VERSION ""

NS_ :

BS_:

BU_: DLG

BO_ 100 DD_TMP_102_Data: 8 Vector__XXX
 SG_ DD_TMP_102_temperature_raw : 0|16@1+ (1,-32768) [-32768|32767] "LSB" Vector__XXX
 SG_ DD_TMP_102_temperature_deg : 16|14@1+ (0.01,-81.92) [-81.92|81.91] "°C" Vector__XXX

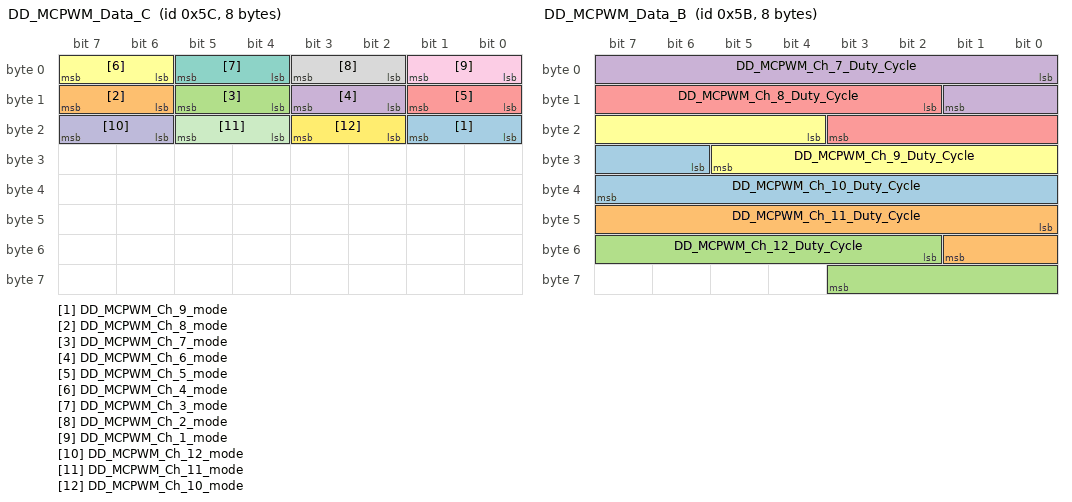
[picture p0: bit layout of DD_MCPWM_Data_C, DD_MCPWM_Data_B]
BO_ 92 DD_MCPWM_Data_C: 8 Vector__XXX
 SG_ DD_MCPWM_Ch_9_mode : 16|2@1+ (1,0) [0|3] "" Vector__XXX
 SG_ DD_MCPWM_Ch_8_mode : 14|2@1+ (1,0) [0|3] "" Vector__XXX
 SG_ DD_MCPWM_Ch_7_mode : 12|2@1+ (1,0) [0|3] "" Vector__XXX
 SG_ DD_MCPWM_Ch_6_mode : 10|2@1+ (1,0) [0|3] "" Vector__XXX
 SG_ DD_MCPWM_Ch_5_mode : 8|2@1+ (1,0) [0|3] "" Vector__XXX
 SG_ DD_MCPWM_Ch_4_mode : 6|2@1+ (1,0) [0|3] "" Vector__XXX
 SG_ DD_MCPWM_Ch_3_mode : 4|2@1+ (1,0) [0|3] "" Vector__XXX
 SG_ DD_MCPWM_Ch_2_mode : 2|2@1+ (1,0) [0|3] "" Vector__XXX
 SG_ DD_MCPWM_Ch_1_mode : 0|2@1+ (1,0) [0|3] "" Vector__XXX
 SG_ DD_MCPWM_Ch_12_mode : 22|2@1+ (1,0) [0|3] "" Vector__XXX
 SG_ DD_MCPWM_Ch_11_mode : 20|2@1+ (1,0) [0|3] "" Vector__XXX
 SG_ DD_MCPWM_Ch_10_mode : 18|2@1+ (1,0) [0|3] "" Vector__XXX

BO_ 91 DD_MCPWM_Data_B: 8 Vector__XXX
 SG_ DD_MCPWM_Ch_10_Duty_Cycle : 30|10@1+ (0.1,0) [0|102.3] "%" Vector__XXX
 SG_ DD_MCPWM_Ch_11_Duty_Cycle : 40|10@1+ (0.1,0) [0|102.3] "%" Vector__XXX
 SG_ DD_MCPWM_Ch_12_Duty_Cycle : 50|10@1+ (0.1,0) [0|102.3] "%" Vector__XXX
 SG_ DD_MCPWM_Ch_7_Duty_Cycle : 0|10@1+ (0.1,0) [0|102.3] "%" Vector__XXX
 SG_ DD_MCPWM_Ch_8_Duty_Cycle : 10|10@1+ (0.1,0) [0|102.3] "%" Vector__XXX
 SG_ DD_MCPWM_Ch_9_Duty_Cycle : 20|10@1+ (0.1,0) [0|102.3] "%" Vector__XXX

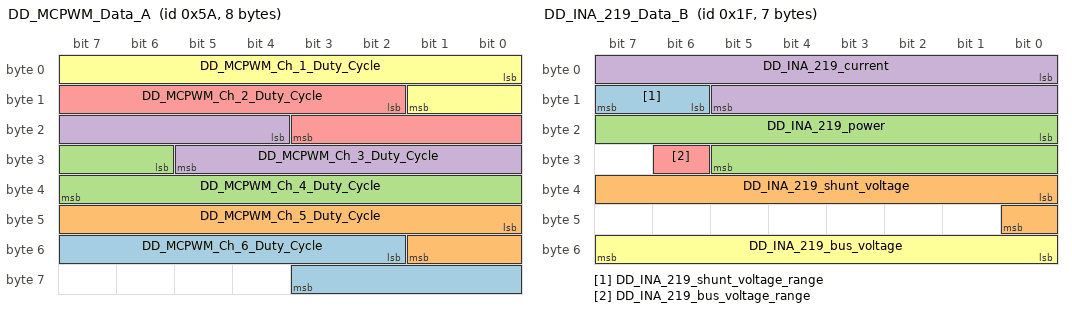
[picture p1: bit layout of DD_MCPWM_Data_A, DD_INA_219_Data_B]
BO_ 90 DD_MCPWM_Data_A: 8 DLG
 SG_ DD_MCPWM_Ch_6_Duty_Cycle : 50|10@1+ (0.1,0) [0|102.3] "%" Vector__XXX
 SG_ DD_MCPWM_Ch_5_Duty_Cycle : 40|10@1+ (0.1,0) [0|102.3] "%" Vector__XXX
 SG_ DD_MCPWM_Ch_4_Duty_Cycle : 30|10@1+ (0.1,0) [0|102.3] "%" Vector__XXX
 SG_ DD_MCPWM_Ch_3_Duty_Cycle : 20|10@1+ (0.1,0) [0|102.3] "%" Vector__XXX
 SG_ DD_MCPWM_Ch_2_Duty_Cycle : 10|10@1+ (0.1,0) [0|102.3] "%" Vector__XXX
 SG_ DD_MCPWM_Ch_1_Duty_Cycle : 0|10@1+ (0.1,0) [0|102.3] "%" Vector__XXX

BO_ 31 DD_INA_219_Data_B: 7 DLG
 SG_ DD_INA_219_shunt_voltage_range : 14|2@1+ (1,0) [0|3] "" Vector__XXX
 SG_ DD_INA_219_shunt_voltage : 32|9@1+ (0.1,0) [0|51.1] "mV" Vector__XXX
 SG_ DD_INA_219_power : 16|14@1+ (0.1,0) [0|1638.3] "mW" Vector__XXX
 SG_ DD_INA_219_current : 0|14@1+ (0.1,0) [0|1638.3] "mA" Vector__XXX
 SG_ DD_INA_219_bus_voltage_range : 30|1@1+ (1,0) [0|1] "" Vector__XXX
 SG_ DD_INA_219_bus_voltage : 48|8@1+ (0.1,0) [0|25.5] "V" Vector__XXX

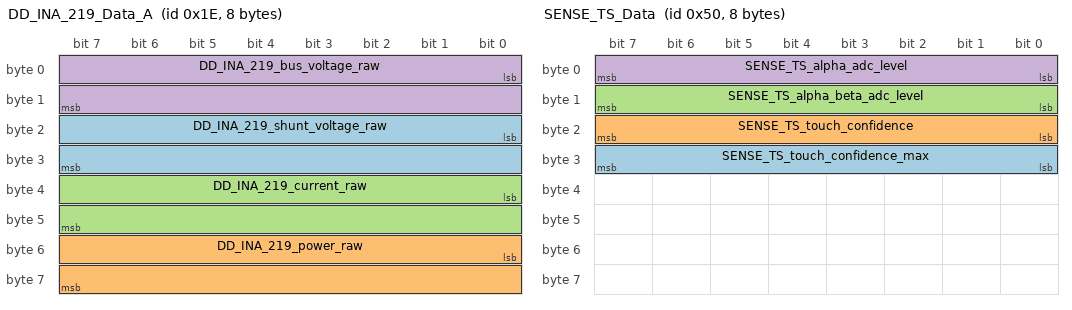
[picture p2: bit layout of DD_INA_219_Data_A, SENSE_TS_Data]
BO_ 30 DD_INA_219_Data_A: 8 DLG
 SG_ DD_INA_219_shunt_voltage_raw : 16|16@1+ (1,-32768) [-32768|32767] "LSB" Vector__XXX
 SG_ DD_INA_219_power_raw : 48|16@1+ (1,0) [0|65535] "LSB" Vector__XXX
 SG_ DD_INA_219_current_raw : 32|16@1+ (1,-32768) [-32768|32767] "LSB" Vector__XXX
 SG_ DD_INA_219_bus_voltage_raw : 0|16@1+ (1,0) [0|65535] "LSB" Vector__XXX

BO_ 80 SENSE_TS_Data: 8 DLG
 SG_ SENSE_TS_touch_confidence_max : 24|8@1+ (0.01,0) [0|2.55] "" Vector__XXX
 SG_ SENSE_TS_touch_confidence : 16|8@1+ (0.01,0) [0|2.55] "" Vector__XXX
 SG_ SENSE_TS_alpha_beta_adc_level : 8|8@1+ (0.01,0) [0|2.55] "" Vector__XXX
 SG_ SENSE_TS_alpha_adc_level : 0|8@1+ (0.01,0) [0|2.55] "" Vector__XXX

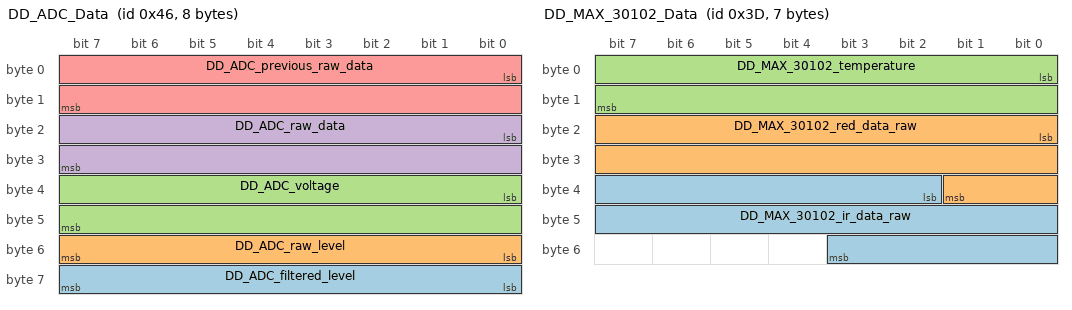
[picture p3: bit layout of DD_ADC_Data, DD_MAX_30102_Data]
BO_ 70 DD_ADC_Data: 8 DLG
 SG_ DD_ADC_filtered_level : 56|8@1+ (0.01,0) [0|2.55] "" Vector__XXX
 SG_ DD_ADC_raw_level : 48|8@1+ (0.01,0) [0|2.55] "" Vector__XXX
 SG_ DD_ADC_voltage : 32|16@1+ (1,0) [0|65535] "mV" Vector__XXX
 SG_ DD_ADC_raw_data : 16|16@1+ (1,0) [0|65535] "" Vector__XXX
 SG_ DD_ADC_previous_raw_data : 0|16@1+ (1,0) [0|65535] "" Vector__XXX

BO_ 61 DD_MAX_30102_Data: 7 DLG
 SG_ DD_MAX_30102_ir_data_raw : 34|18@1+ (1,0) [0|262143] "" Vector__XXX
 SG_ DD_MAX_30102_red_data_raw : 16|18@1+ (1,0) [0|262143] "" Vector__XXX
 SG_ DD_MAX_30102_temperature : 0|16@1+ (0.01,-327.68) [-327.68|327.67] "deg" Vector__XXX

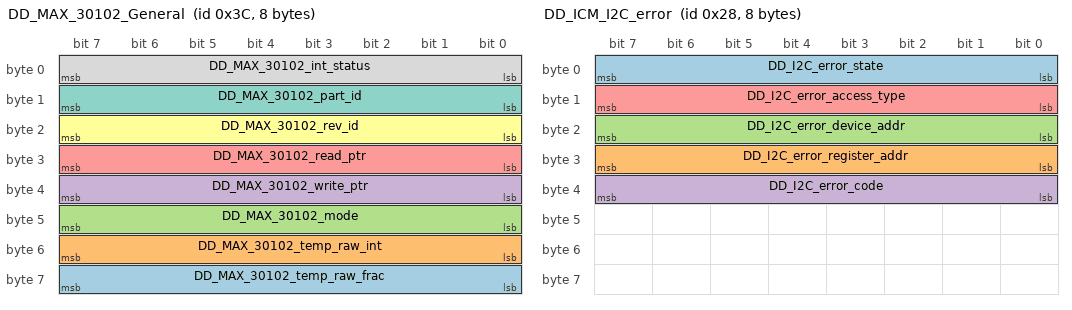
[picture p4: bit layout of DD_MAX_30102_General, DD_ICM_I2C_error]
BO_ 60 DD_MAX_30102_General: 8 DLG
 SG_ DD_MAX_30102_temp_raw_frac : 56|8@1+ (1,0) [0|255] "" Vector__XXX
 SG_ DD_MAX_30102_temp_raw_int : 48|8@1+ (1,0) [0|255] "" Vector__XXX
 SG_ DD_MAX_30102_mode : 40|8@1+ (1,0) [0|255] "" Vector__XXX
 SG_ DD_MAX_30102_write_ptr : 32|8@1+ (1,0) [0|255] "" Vector__XXX
 SG_ DD_MAX_30102_read_ptr : 24|8@1+ (1,0) [0|255] "" Vector__XXX
 SG_ DD_MAX_30102_rev_id : 16|8@1+ (1,0) [0|255] "" Vector__XXX
 SG_ DD_MAX_30102_part_id : 8|8@1+ (1,0) [0|255] "" Vector__XXX
 SG_ DD_MAX_30102_int_status : 0|8@1+ (1,0) [0|255] "" Vector__XXX

BO_ 50 DLG_LOG_General: 1 DLG
 SG_ DLG_LOG_global_msg_counter : 0|8@1+ (1,0) [0|255] "" Vector__XXX

BO_ 40 DD_ICM_I2C_error: 8 DLG
 SG_ DD_I2C_error_state : 0|8@1+ (1,0) [0|255] "" Vector__XXX
 SG_ DD_I2C_error_register_addr : 24|8@1+ (1,0) [0|255] "" Vector__XXX
 SG_ DD_I2C_error_device_addr : 16|8@1+ (1,0) [0|255] "" Vector__XXX
 SG_ DD_I2C_error_code : 32|8@1+ (1,-128) [-128|127] "" Vector__XXX
 SG_ DD_I2C_error_access_type : 8|8@1+ (1,0) [0|255] "" Vector__XXX

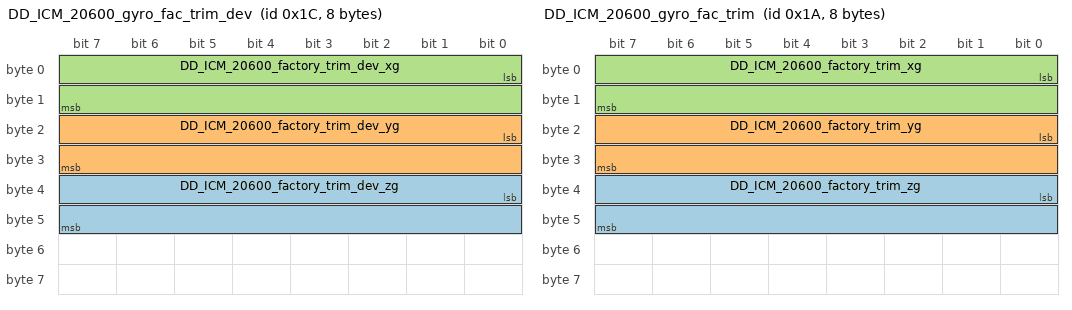
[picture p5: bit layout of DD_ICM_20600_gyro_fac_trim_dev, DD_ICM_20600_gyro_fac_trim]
BO_ 28 DD_ICM_20600_gyro_fac_trim_dev: 8 DLG
 SG_ DD_ICM_20600_factory_trim_dev_zg : 32|16@1+ (0.001,-32.768) [-32.768|32.767] "" Vector__XXX
 SG_ DD_ICM_20600_factory_trim_dev_yg : 16|16@1+ (0.001,-32.768) [-32.768|32.767] "" Vector__XXX
 SG_ DD_ICM_20600_factory_trim_dev_xg : 0|16@1+ (0.001,-32.768) [-32.768|32.767] "" Vector__XXX

BO_ 26 DD_ICM_20600_gyro_fac_trim: 8 DLG
 SG_ DD_ICM_20600_factory_trim_zg : 32|16@1+ (1,-32768) [-32768|32767] "" Vector__XXX
 SG_ DD_ICM_20600_factory_trim_yg : 16|16@1+ (1,-32768) [-32768|32767] "" Vector__XXX
 SG_ DD_ICM_20600_factory_trim_xg : 0|16@1+ (1,-32768) [-32768|32767] "" Vector__XXX

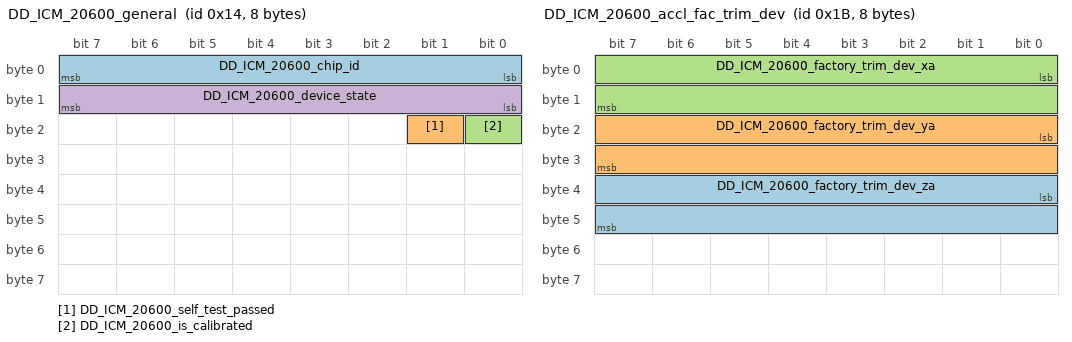
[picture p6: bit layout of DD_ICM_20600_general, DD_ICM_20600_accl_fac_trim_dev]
BO_ 20 DD_ICM_20600_general: 8 DLG
 SG_ DD_ICM_20600_chip_id : 0|8@1+ (1,0) [0|255] "" Vector__XXX
 SG_ DD_ICM_20600_self_test_passed : 17|1@1+ (1,0) [0|1] "" Vector__XXX
 SG_ DD_ICM_20600_is_calibrated : 16|1@1+ (1,0) [0|1] "" Vector__XXX
 SG_ DD_ICM_20600_device_state : 8|8@1+ (1,0) [0|255] "" Vector__XXX

BO_ 27 DD_ICM_20600_accl_fac_trim_dev: 8 DLG
 SG_ DD_ICM_20600_factory_trim_dev_za : 32|16@1+ (0.001,-32.768) [-32.768|32.767] "" Vector__XXX
 SG_ DD_ICM_20600_factory_trim_dev_ya : 16|16@1+ (0.001,-32.768) [-32.768|32.767] "" Vector__XXX
 SG_ DD_ICM_20600_factory_trim_dev_xa : 0|16@1+ (0.001,-32.768) [-32.768|32.767] "" Vector__XXX

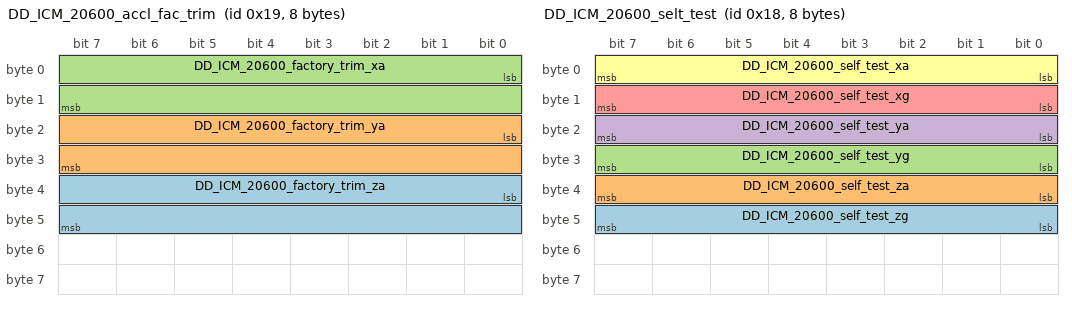
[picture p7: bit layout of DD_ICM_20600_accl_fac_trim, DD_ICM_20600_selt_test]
BO_ 25 DD_ICM_20600_accl_fac_trim: 8 DLG
 SG_ DD_ICM_20600_factory_trim_za : 32|16@1+ (1,-32768) [-32768|32767] "" Vector__XXX
 SG_ DD_ICM_20600_factory_trim_ya : 16|16@1+ (1,-32768) [-32768|32767] "" Vector__XXX
 SG_ DD_ICM_20600_factory_trim_xa : 0|16@1+ (1,-32768) [-32768|32767] "" Vector__XXX

BO_ 24 DD_ICM_20600_selt_test: 8 DLG
 SG_ DD_ICM_20600_self_test_zg : 40|8@1+ (1,0) [0|255] "" Vector__XXX
 SG_ DD_ICM_20600_self_test_za : 32|8@1+ (1,0) [0|255] "" Vector__XXX
 SG_ DD_ICM_20600_self_test_yg : 24|8@1+ (1,0) [0|255] "" Vector__XXX
 SG_ DD_ICM_20600_self_test_ya : 16|8@1+ (1,0) [0|255] "" Vector__XXX
 SG_ DD_ICM_20600_self_test_xg : 8|8@1+ (1,0) [0|255] "" Vector__XXX
 SG_ DD_ICM_20600_self_test_xa : 0|8@1+ (1,0) [0|255] "" Vector__XXX

BO_ 23 DD_ICM_20600_temperature: 8 DLG
 SG_ DD_ICM_20600_temperature_deg : 16|16@1+ (0.01,-327.68) [-327.68|327.67] "deg" Vector__XXX
 SG_ DD_ICM_20600_temperature_raw : 0|16@1+ (1,0) [0|65535] "" Vector__XXX

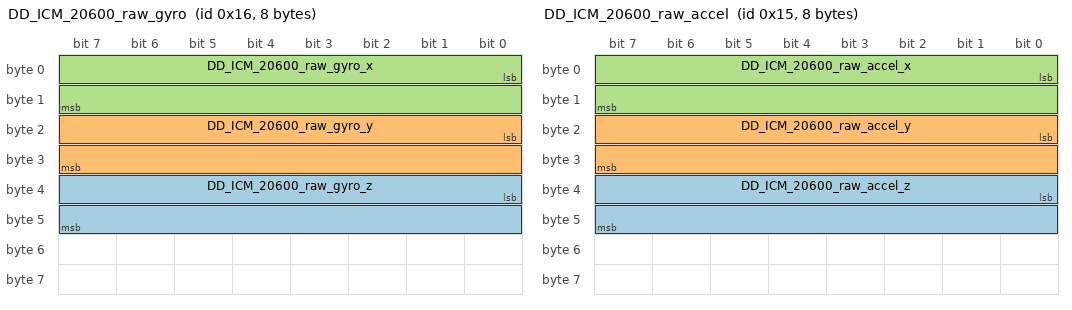
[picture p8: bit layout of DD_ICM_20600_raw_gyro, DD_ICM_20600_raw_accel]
BO_ 22 DD_ICM_20600_raw_gyro: 8 DLG
 SG_ DD_ICM_20600_raw_gyro_z : 32|16@1+ (1,-32768) [-32768|32767] "" Vector__XXX
 SG_ DD_ICM_20600_raw_gyro_y : 16|16@1+ (1,-32768) [-32768|32767] "" Vector__XXX
 SG_ DD_ICM_20600_raw_gyro_x : 0|16@1+ (1,-32768) [-32768|32767] "" Vector__XXX

BO_ 21 DD_ICM_20600_raw_accel: 8 DLG
 SG_ DD_ICM_20600_raw_accel_z : 32|16@1+ (1,-32768) [-32768|32767] "" Vector__XXX
 SG_ DD_ICM_20600_raw_accel_y : 16|16@1+ (1,-32768) [-32768|32767] "" Vector__XXX
 SG_ DD_ICM_20600_raw_accel_x : 0|16@1+ (1,-32768) [-32768|32767] "" Vector__XXX

CM_ SG_ 100 DD_TMP_102_temperature_raw "Current temperature reading in LSB (0.0625°C / LSB)";
CM_ SG_ 100 DD_TMP_102_temperature_deg "Current temperature reading in °C";
CM_ SG_ 92 DD_MCPWM_Ch_9_mode "Current alpha filtered ADC value";
CM_ SG_ 92 DD_MCPWM_Ch_8_mode "Current alpha filtered ADC value";
CM_ SG_ 92 DD_MCPWM_Ch_7_mode "Current alpha filtered ADC value";
CM_ SG_ 92 DD_MCPWM_Ch_6_mode "Current alpha filtered ADC value";
CM_ SG_ 92 DD_MCPWM_Ch_5_mode "Current alpha filtered ADC value";
CM_ SG_ 92 DD_MCPWM_Ch_4_mode "Current alpha filtered ADC value";
CM_ SG_ 92 DD_MCPWM_Ch_3_mode "Current alpha filtered ADC value";
CM_ SG_ 92 DD_MCPWM_Ch_2_mode "Current alpha filtered ADC value";
CM_ SG_ 92 DD_MCPWM_Ch_1_mode "Current alpha filtered ADC value";
CM_ SG_ 92 DD_MCPWM_Ch_12_mode "Current alpha filtered ADC value";
CM_ SG_ 92 DD_MCPWM_Ch_11_mode "Current alpha filtered ADC value";
CM_ SG_ 92 DD_MCPWM_Ch_10_mode "Current alpha filtered ADC value";
CM_ SG_ 91 DD_MCPWM_Ch_10_Duty_Cycle "Current alpha filtered ADC value";
CM_ SG_ 91 DD_MCPWM_Ch_11_Duty_Cycle "Current alpha filtered ADC value";
CM_ SG_ 91 DD_MCPWM_Ch_12_Duty_Cycle "Current alpha filtered ADC value";
CM_ SG_ 91 DD_MCPWM_Ch_7_Duty_Cycle "Current alpha filtered ADC value";
CM_ SG_ 91 DD_MCPWM_Ch_8_Duty_Cycle "Current alpha filtered ADC value";
CM_ SG_ 91 DD_MCPWM_Ch_9_Duty_Cycle "Current alpha filtered ADC value";
CM_ SG_ 90 DD_MCPWM_Ch_6_Duty_Cycle "Current alpha filtered ADC value";
CM_ SG_ 90 DD_MCPWM_Ch_5_Duty_Cycle "Current alpha filtered ADC value";
CM_ SG_ 90 DD_MCPWM_Ch_4_Duty_Cycle "Current alpha filtered ADC value";
CM_ SG_ 90 DD_MCPWM_Ch_3_Duty_Cycle "Current alpha filtered ADC value";
CM_ SG_ 90 DD_MCPWM_Ch_2_Duty_Cycle "Current alpha filtered ADC value";
CM_ SG_ 90 DD_MCPWM_Ch_1_Duty_Cycle "Current alpha filtered ADC value";
CM_ SG_ 31 DD_INA_219_shunt_voltage_range "Current alpha filtered ADC value";
CM_ SG_ 31 DD_INA_219_shunt_voltage "Current alpha filtered ADC value";
CM_ SG_ 31 DD_INA_219_power "Current alpha filtered ADC value";
CM_ SG_ 31 DD_INA_219_current "Current alpha filtered ADC value";
CM_ SG_ 31 DD_INA_219_bus_voltage_range "Current alpha filtered ADC value";
CM_ SG_ 31 DD_INA_219_bus_voltage "Current alpha filtered ADC value";
CM_ SG_ 30 DD_INA_219_shunt_voltage_raw "Current alpha filtered ADC value";
CM_ SG_ 30 DD_INA_219_power_raw "Current alpha filtered ADC value";
CM_ SG_ 30 DD_INA_219_current_raw "Current alpha filtered ADC value";
CM_ SG_ 30 DD_INA_219_bus_voltage_raw "Current alpha filtered ADC value";
CM_ SG_ 80 SENSE_TS_touch_confidence_max "Maximum touch confidence with a range of 0.0 to 1.0";
CM_ SG_ 80 SENSE_TS_touch_confidence "Touch confidence with a range of 0.0 to 1.0";
CM_ SG_ 80 SENSE_TS_alpha_beta_adc_level "Current alpha/beta  filtered ADC value";
CM_ SG_ 80 SENSE_TS_alpha_adc_level "Current alpha filtered ADC value";
BA_DEF_ SG_  "GenSigSendType" ENUM  "Cyclic","OnWrite","OnWriteWithRepetition","OnChange","OnChangeWithRepetition","IfActive","IfActiveWithRepetition","NoSigSendType";
BA_DEF_  "DBName" STRING ;
BA_DEF_ BO_  "GenMsgSendType" ENUM  "Cyclic","not_used","not_used","not_used","not_used","Cyclic","not_used","IfActive","NoMsgSendType";
BA_DEF_  "BusType" STRING ;
BA_DEF_DEF_  "GenSigSendType" "Cyclic";
BA_DEF_DEF_  "DBName" "";
BA_DEF_DEF_  "GenMsgSendType" "NoMsgSendType";
BA_DEF_DEF_  "BusType" "";
BA_ "BusType" "CAN";
BA_ "DBName" "DLG";
VAL_ 92 DD_MCPWM_Ch_9_mode 2 "DD_MCPWM_MODE_PWM" 1 "DD_MCPWM_MODE_ON" 0 "DD_MCPWM_MODE_OFF" ;
VAL_ 92 DD_MCPWM_Ch_8_mode 2 "DD_MCPWM_MODE_PWM" 1 "DD_MCPWM_MODE_ON" 0 "DD_MCPWM_MODE_OFF" ;
VAL_ 92 DD_MCPWM_Ch_7_mode 2 "DD_MCPWM_MODE_PWM" 1 "DD_MCPWM_MODE_ON" 0 "DD_MCPWM_MODE_OFF" ;
VAL_ 92 DD_MCPWM_Ch_6_mode 2 "DD_MCPWM_MODE_PWM" 1 "DD_MCPWM_MODE_ON" 0 "DD_MCPWM_MODE_OFF" ;
VAL_ 92 DD_MCPWM_Ch_5_mode 2 "DD_MCPWM_MODE_PWM" 1 "DD_MCPWM_MODE_ON" 0 "DD_MCPWM_MODE_OFF" ;
VAL_ 92 DD_MCPWM_Ch_4_mode 2 "DD_MCPWM_MODE_PWM" 1 "DD_MCPWM_MODE_ON" 0 "DD_MCPWM_MODE_OFF" ;
VAL_ 92 DD_MCPWM_Ch_3_mode 2 "DD_MCPWM_MODE_PWM" 1 "DD_MCPWM_MODE_ON" 0 "DD_MCPWM_MODE_OFF" ;
VAL_ 92 DD_MCPWM_Ch_2_mode 2 "DD_MCPWM_MODE_PWM" 1 "DD_MCPWM_MODE_ON" 0 "DD_MCPWM_MODE_OFF" ;
VAL_ 92 DD_MCPWM_Ch_1_mode 2 "DD_MCPWM_MODE_PWM" 1 "DD_MCPWM_MODE_ON" 0 "DD_MCPWM_MODE_OFF" ;
VAL_ 92 DD_MCPWM_Ch_12_mode 2 "DD_MCPWM_MODE_PWM" 1 "DD_MCPWM_MODE_ON" 0 "DD_MCPWM_MODE_OFF" ;
VAL_ 92 DD_MCPWM_Ch_11_mode 2 "DD_MCPWM_MODE_PWM" 1 "DD_MCPWM_MODE_ON" 0 "DD_MCPWM_MODE_OFF" ;
VAL_ 92 DD_MCPWM_Ch_10_mode 2 "DD_MCPWM_MODE_PWM" 1 "DD_MCPWM_MODE_ON" 0 "DD_MCPWM_MODE_OFF" ;
VAL_ 31 DD_INA_219_shunt_voltage_range 3 "DD_INA_219_SHUNT_VOL_RANGE_320MV" 2 "DD_INA_219_SHUNT_VOL_RANGE_160MV" 1 "DD_INA_219_SHUNT_VOL_RANGE_80MV" 0 "DD_INA_219_SHUNT_VOL_RANGE_40MV" ;
VAL_ 31 DD_INA_219_bus_voltage_range 1 "DD_INA_219_BUS_VOL_RANGE_32V" 0 "DD_INA_219_BUS_VOL_RANGE_16V" ;
VAL_ 60 DD_MAX_30102_mode 3 "DD_MAX_30102_MODE_MULTI_LED" 2 "DD_MAX_30102_MODE_SPO2" 1 "DD_MAX_30102_MODE_HR" 0 "DD_MAX_30102_MODE_SLEEP" ;
VAL_ 40 DD_I2C_error_state 1 "Error" 0 "Running" ;
VAL_ 40 DD_I2C_error_device_addr 104 "DD_ICM_20600" 87 "DD_MAX_30102" ;
VAL_ 40 DD_I2C_error_code 263 "DD_I2C_ERROR_TIMEOUT" 260 "DD_I2C_ERROR_INVALID_SIZE" 258 "DD_I2C_ERROR_INVALID_ARG" 0 "DD_I2C_ERROR_OK" -1 "DD_I2C_ERROR_FAIL" ;
VAL_ 40 DD_I2C_error_access_type 3 "DD_I2C_ACCESS_TYPE_WD_BURST" 2 "DD_I2C_ACCESS_TYPE_WD_SINGLE" 1 "DD_I2C_ACCESS_TYPE_RD_BURST" 0 "DD_I2C_ACCESS_TYPE_RD_SINGLE" ;
VAL_ 20 DD_ICM_20600_self_test_passed 1 "Passed" 0 "Failed" ;
VAL_ 20 DD_ICM_20600_is_calibrated 1 "Calibrated" 0 "Not Calibrated" ;
VAL_ 20 DD_ICM_20600_device_state 3 "DD_STATE_RUN" 2 "DD_STATE_CALIB" 1 "DD_STATE_TEST" 0 "DD_STATE_INIT" ;
